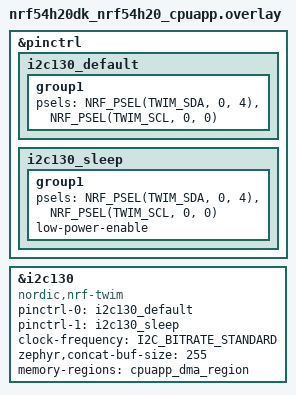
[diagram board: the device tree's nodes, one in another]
/*
 * Copyright (c) 2024 Nordic Semiconductor ASA
 *
 * SPDX-License-Identifier: LicenseRef-Nordic-5-Clause
 */

&pinctrl {
	i2c130_default: i2c130_default {
		group1 {
			psels = <NRF_PSEL(TWIM_SDA, 0, 4)>,
				<NRF_PSEL(TWIM_SCL, 0, 0)>;
		};
	};

	i2c130_sleep: i2c130_sleep {
		group1 {
			psels = <NRF_PSEL(TWIM_SDA, 0, 4)>,
				<NRF_PSEL(TWIM_SCL, 0, 0)>;
			low-power-enable;
		};
	};
};

/* Define arduino_i2c here so it is available for the shield overlay */
arduino_i2c: &i2c130 {
	compatible = "nordic,nrf-twim";
	pinctrl-0 = <&i2c130_default>;
	pinctrl-1 = <&i2c130_sleep>;
	pinctrl-names = "default", "sleep";
	clock-frequency = <I2C_BITRATE_STANDARD>;
	zephyr,concat-buf-size = <255>;
	memory-regions = <&cpuapp_dma_region>;
};
